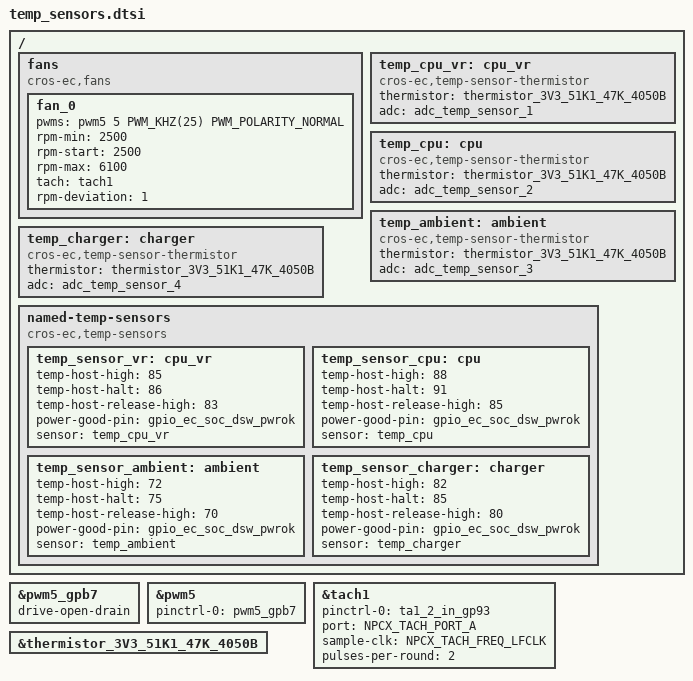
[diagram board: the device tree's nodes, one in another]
/* Copyright 2025 The ChromiumOS Authors
 * Use of this source code is governed by a BSD-style license that can be
 * found in the LICENSE file.
 */

#include <cros/thermistor/thermistor.dtsi>

/ {

	fans {
		compatible = "cros-ec,fans";

		fan_0 {
			pwms = <&pwm5 5 PWM_KHZ(25) PWM_POLARITY_NORMAL>;
			rpm-min = <2500>;
			rpm-start = <2500>;
			rpm-max = <6100>;
			tach = <&tach1>;
			rpm-deviation = <1>;
		};
	};

	temp_cpu_vr: cpu_vr {
		compatible = "cros-ec,temp-sensor-thermistor";
		thermistor = <&thermistor_3V3_51K1_47K_4050B>;
		adc = <&adc_temp_sensor_1>;
	};
	temp_cpu: cpu {
		compatible = "cros-ec,temp-sensor-thermistor";
		thermistor = <&thermistor_3V3_51K1_47K_4050B>;
		adc = <&adc_temp_sensor_2>;
	};
	temp_ambient: ambient {
		compatible = "cros-ec,temp-sensor-thermistor";
		thermistor = <&thermistor_3V3_51K1_47K_4050B>;
		adc = <&adc_temp_sensor_3>;
	};
	temp_charger: charger {
		compatible = "cros-ec,temp-sensor-thermistor";
		thermistor = <&thermistor_3V3_51K1_47K_4050B>;
		adc = <&adc_temp_sensor_4>;
	};

	named-temp-sensors {
		compatible = "cros-ec,temp-sensors";
		temp_sensor_vr: cpu_vr {
			temp-host-high = <85>;
			temp-host-halt = <86>;
			temp-host-release-high = <83>;
			power-good-pin = <&gpio_ec_soc_dsw_pwrok>;
			sensor = <&temp_cpu_vr>;
		};
		temp_sensor_cpu: cpu {
			temp-host-high = <88>;
			temp-host-halt = <91>;
			temp-host-release-high = <85>;
			power-good-pin = <&gpio_ec_soc_dsw_pwrok>;
			sensor = <&temp_cpu>;
		};
		temp_sensor_ambient: ambient {
			temp-host-high = <72>;
			temp-host-halt = <75>;
			temp-host-release-high = <70>;
			power-good-pin = <&gpio_ec_soc_dsw_pwrok>;
			sensor = <&temp_ambient>;
		};
		temp_sensor_charger: charger {
			temp-host-high = <82>;
			temp-host-halt = <85>;
			temp-host-release-high = <80>;
			power-good-pin = <&gpio_ec_soc_dsw_pwrok>;
			sensor = <&temp_charger>;
		};
	};
};

&pwm5_gpb7 {
	drive-open-drain;
};

&pwm5 {
	status = "okay";
	pinctrl-0 = <&pwm5_gpb7>;
	pinctrl-names = "default";
};

/* Tachometer for fan speed measurement */
&tach1 {
	status = "okay";
	pinctrl-0 = <&ta1_2_in_gp93>;
	pinctrl-names = "default";
	port = <NPCX_TACH_PORT_A>; /* port-A is selected */
	sample-clk = <NPCX_TACH_FREQ_LFCLK>; /* Use LFCLK as sampling clock */
	pulses-per-round = <2>; /* number of pulses per round of encoder */
};

&thermistor_3V3_51K1_47K_4050B {
	status = "okay";
};
